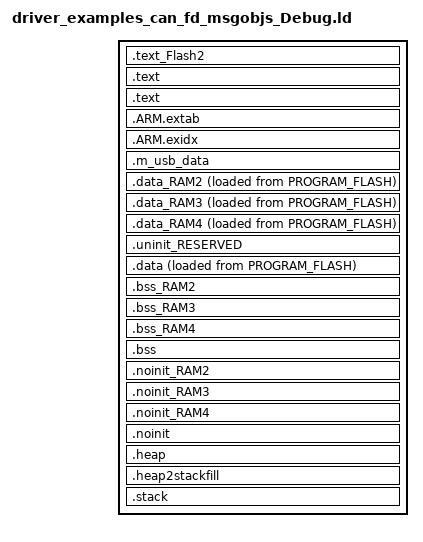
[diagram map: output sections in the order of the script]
/*
 * GENERATED FILE - DO NOT EDIT
 * (c) Code Red Technologies Ltd, 2008-2013
 * (c) NXP Semiconductors 2013-2017
 * Generated linker script file for LPC54608J512
 * Created from linkscript.ldt by FMCreateLinkLibraries
 * Using Freemarker v2.3.23
 * MCUXpresso IDE v10.0.0 [Build 344] [2017-03-21]  on Apr 3, 2017 10:12:03 AM
 */

INCLUDE "driver_examples_can_fd_msgobjs_Debug_library.ld"
INCLUDE "driver_examples_can_fd_msgobjs_Debug_memory.ld"

ENTRY(ResetISR)

SECTIONS
{
    .text_Flash2 : ALIGN(4)
    {
       FILL(0xff)
    	*(.text_Flash2*) /* for compatibility with previous releases */
    	*(.text_BOARD_FLASH*) /* for compatibility with previous releases */
    	*(.text.$Flash2*)
    	*(.text.$BOARD_FLASH*)
    	*(.rodata.$Flash2*)
    	*(.rodata.$BOARD_FLASH*)
    } > BOARD_FLASH

    /* MAIN TEXT SECTION */
    .text : ALIGN(4)
    {
        FILL(0xff)
        __vectors_start__ = ABSOLUTE(.) ;
        KEEP(*(.isr_vector))
        /* Global Section Table */
        . = ALIGN(4) ;
        __section_table_start = .;
        __data_section_table = .;
        LONG(LOADADDR(.data));
        LONG(    ADDR(.data));
        LONG(  SIZEOF(.data));
        LONG(LOADADDR(.data_RAM2));
        LONG(    ADDR(.data_RAM2));
        LONG(  SIZEOF(.data_RAM2));
        LONG(LOADADDR(.data_RAM3));
        LONG(    ADDR(.data_RAM3));
        LONG(  SIZEOF(.data_RAM3));
        LONG(LOADADDR(.data_RAM4));
        LONG(    ADDR(.data_RAM4));
        LONG(  SIZEOF(.data_RAM4));
        __data_section_table_end = .;
        __bss_section_table = .;
        LONG(    ADDR(.bss));
        LONG(  SIZEOF(.bss));
        LONG(    ADDR(.bss_RAM2));
        LONG(  SIZEOF(.bss_RAM2));
        LONG(    ADDR(.bss_RAM3));
        LONG(  SIZEOF(.bss_RAM3));
        LONG(    ADDR(.bss_RAM4));
        LONG(  SIZEOF(.bss_RAM4));
        __bss_section_table_end = .;
        __section_table_end = . ;
	    /* End of Global Section Table */

        *(.after_vectors*)



    } >PROGRAM_FLASH

    .text : ALIGN(4)
    {
        *(.text*)
        *(.rodata .rodata.* .constdata .constdata.*)
        . = ALIGN(4);
    } > PROGRAM_FLASH
    /*
     * for exception handling/unwind - some Newlib functions (in common
     * with C++ and STDC++) use this. 
     */
    .ARM.extab : ALIGN(4) 
    {
        *(.ARM.extab* .gnu.linkonce.armextab.*)
    } > PROGRAM_FLASH
    __exidx_start = .;

    .ARM.exidx : ALIGN(4)
    {
        *(.ARM.exidx* .gnu.linkonce.armexidx.*)
    } > PROGRAM_FLASH
    __exidx_end = .;

    _etext = .;
        
 
	/* USB_RAM */
    .m_usb_data (NOLOAD) :
    {
        *(m_usb_global)
    } > USB_RAM
    /* DATA section for SRAMX */
    .data_RAM2 : ALIGN(4)
    {
        FILL(0xff)
        PROVIDE(__start_data_RAM2 = .) ;
        *(.ramfunc.$RAM2)
        *(.ramfunc.$SRAMX)
        *(.data.$RAM2*)
        *(.data.$SRAMX*)
        . = ALIGN(4) ;
        PROVIDE(__end_data_RAM2 = .) ;
     } > SRAMX AT>PROGRAM_FLASH

    /* DATA section for USB_RAM */
    .data_RAM3 : ALIGN(4)
    {
        FILL(0xff)
        PROVIDE(__start_data_RAM3 = .) ;
        *(.ramfunc.$RAM3)
        *(.ramfunc.$USB_RAM)
        *(.data.$RAM3*)
        *(.data.$USB_RAM*)
        . = ALIGN(4) ;
        PROVIDE(__end_data_RAM3 = .) ;
     } > USB_RAM AT>PROGRAM_FLASH

    /* DATA section for BOARD_SDRAM */
    .data_RAM4 : ALIGN(4)
    {
        FILL(0xff)
        PROVIDE(__start_data_RAM4 = .) ;
        *(.ramfunc.$RAM4)
        *(.ramfunc.$BOARD_SDRAM)
        *(.data.$RAM4*)
        *(.data.$BOARD_SDRAM*)
        . = ALIGN(4) ;
        PROVIDE(__end_data_RAM4 = .) ;
     } > BOARD_SDRAM AT>PROGRAM_FLASH

    /* MAIN DATA SECTION */
    .uninit_RESERVED : ALIGN(4)
    {
        KEEP(*(.bss.$RESERVED*))
        . = ALIGN(4) ;
        _end_uninit_RESERVED = .;
    } > SRAM_0_1_2_3
    /* Main DATA section (SRAM_0_1_2_3) */
    .data : ALIGN(4)
    {
       FILL(0xff)
       _data = . ;
       *(vtable)
       *(.ramfunc*)
       *(.data*)
       . = ALIGN(4) ;
       _edata = . ;
    } > SRAM_0_1_2_3 AT>PROGRAM_FLASH
    /* BSS section for SRAMX */
    .bss_RAM2 : ALIGN(4)
    {
       PROVIDE(__start_bss_RAM2 = .) ;
       *(.bss.$RAM2*)
       *(.bss.$SRAMX*)
       . = ALIGN (. != 0 ? 4 : 1) ; /* avoid empty segment */
       PROVIDE(__end_bss_RAM2 = .) ;
    } > SRAMX 
    /* BSS section for USB_RAM */
    .bss_RAM3 : ALIGN(4)
    {
       PROVIDE(__start_bss_RAM3 = .) ;
       *(.bss.$RAM3*)
       *(.bss.$USB_RAM*)
       . = ALIGN (. != 0 ? 4 : 1) ; /* avoid empty segment */
       PROVIDE(__end_bss_RAM3 = .) ;
    } > USB_RAM 
    /* BSS section for BOARD_SDRAM */
    .bss_RAM4 : ALIGN(4)
    {
       PROVIDE(__start_bss_RAM4 = .) ;
       *(.bss.$RAM4*)
       *(.bss.$BOARD_SDRAM*)
       . = ALIGN (. != 0 ? 4 : 1) ; /* avoid empty segment */
       PROVIDE(__end_bss_RAM4 = .) ;
    } > BOARD_SDRAM 
    /* MAIN BSS SECTION */
    .bss : ALIGN(4)
    {
        _bss = .;
        *(.bss*)
        *(COMMON)
        . = ALIGN(4) ;
        _ebss = .;
        PROVIDE(end = .);
    } > SRAM_0_1_2_3
    /* NOINIT section for SRAMX */
    .noinit_RAM2 (NOLOAD) : ALIGN(4)
    {
       *(.noinit.$RAM2*)
       *(.noinit.$SRAMX*)
       . = ALIGN(4) ;
    } > SRAMX 
    /* NOINIT section for USB_RAM */
    .noinit_RAM3 (NOLOAD) : ALIGN(4)
    {
       *(.noinit.$RAM3*)
       *(.noinit.$USB_RAM*)
       . = ALIGN(4) ;
    } > USB_RAM 
    /* NOINIT section for BOARD_SDRAM */
    .noinit_RAM4 (NOLOAD) : ALIGN(4)
    {
       *(.noinit.$RAM4*)
       *(.noinit.$BOARD_SDRAM*)
       . = ALIGN(4) ;
    } > BOARD_SDRAM 
    /* DEFAULT NOINIT SECTION */
    .noinit (NOLOAD): ALIGN(4)
    {
        _noinit = .;
        *(.noinit*) 
         . = ALIGN(4) ;
        _end_noinit = .;
    } > SRAM_0_1_2_3
    .heap :  ALIGN(4)
    {
        _pvHeapStart = .;
        . += 0x1000;
		. = ALIGN(4);
		_pvHeapLimit = .;
    } > SRAM_0_1_2_3
       .heap2stackfill  : 
	{
		. += 0x1000;
	} > SRAM_0_1_2_3
	.stack ORIGIN(SRAM_0_1_2_3) + LENGTH(SRAM_0_1_2_3) - 0x1000 - 0:  ALIGN(4)
	{
		_vStackBase = .;
		. = ALIGN(4);
		_vStackTop = . + 0x1000;
	} > SRAM_0_1_2_3

    /* ## Create checksum value (used in startup) ## */
    PROVIDE(__valid_user_code_checksum = 0 - 
                                         (_vStackTop 
                                         + (ResetISR + 1) 
                                         + (NMI_Handler + 1) 
                                         + (HardFault_Handler + 1) 
                                         + (( DEFINED(MemManage_Handler) ? MemManage_Handler : 0 ) + 1)   /* MemManage_Handler may not be defined */
                                         + (( DEFINED(BusFault_Handler) ? BusFault_Handler : 0 ) + 1)     /* BusFault_Handler may not be defined */
                                         + (( DEFINED(UsageFault_Handler) ? UsageFault_Handler : 0 ) + 1) /* UsageFault_Handler may not be defined */
                                         ) );
}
